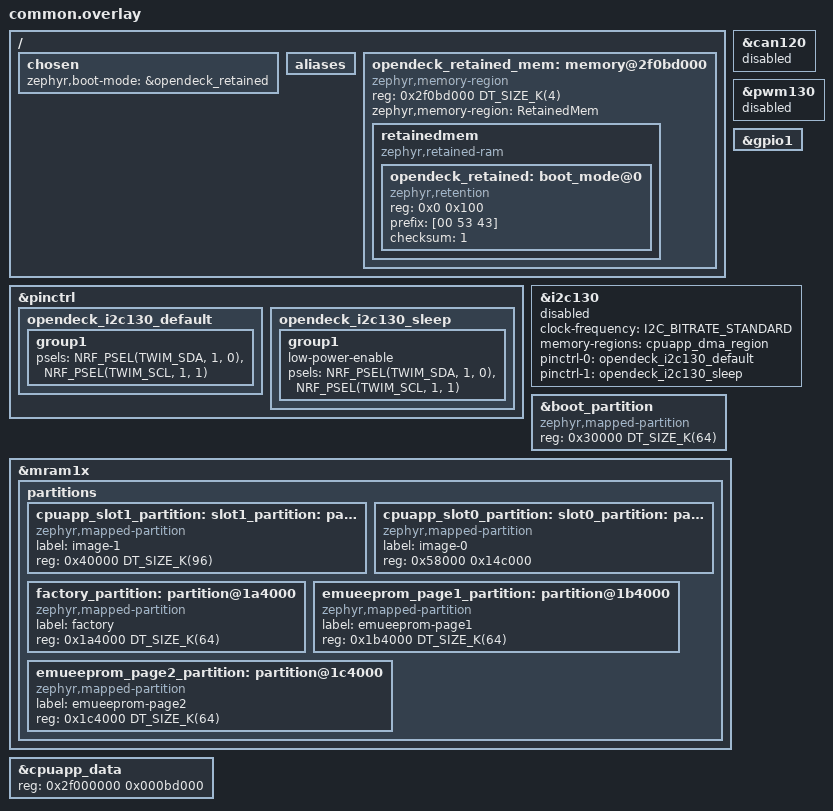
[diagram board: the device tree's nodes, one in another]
#include <zephyr/dt-bindings/i2c/i2c.h>

&can120 {
    status = "disabled";
};

/ {
    chosen {
        /delete-property/ zephyr,canbus;
    };

    aliases {
        /delete-property/ led0;
        /delete-property/ led1;
        /delete-property/ led2;
        /delete-property/ led3;
        /delete-property/ pwm-led0;
        /delete-property/ mcuboot-led0;
        /delete-property/ sw0;
        /delete-property/ sw1;
        /delete-property/ sw2;
        /delete-property/ sw3;
        /delete-property/ mcuboot-button0;
    };

    /delete-node/ buttons;
    /delete-node/ leds;
    /delete-node/ pwmleds;
};

&pinctrl {
    opendeck_i2c130_default: opendeck_i2c130_default {
        group1 {
            psels = <NRF_PSEL(TWIM_SDA, 1, 0)>,
                <NRF_PSEL(TWIM_SCL, 1, 1)>;
        };
    };

    opendeck_i2c130_sleep: opendeck_i2c130_sleep {
        group1 {
            low-power-enable;
            psels = <NRF_PSEL(TWIM_SDA, 1, 0)>,
                <NRF_PSEL(TWIM_SCL, 1, 1)>;
        };
    };
};

&pwm130 {
    status = "disabled";
};

&gpio1 {
    status = "okay";
};

&i2c130 {
    status = "disabled";
    clock-frequency = <I2C_BITRATE_STANDARD>;
    memory-regions = <&cpuapp_dma_region>;
    pinctrl-0 = <&opendeck_i2c130_default>;
    pinctrl-1 = <&opendeck_i2c130_sleep>;
    pinctrl-names = "default", "sleep";
};

&boot_partition {
    compatible = "zephyr,mapped-partition";
    reg = <0x30000 DT_SIZE_K(64)>;
};

&mram1x {
    partitions {
        ranges;
        /delete-node/ partition@40000;
        /delete-node/ partition@100000;
        /delete-node/ partition@1a4000;
        /delete-node/ partition@1ae000;
        /delete-node/ partition@1b0000;
        /delete-node/ partition@1c0000;
        /delete-node/ partition@1c2000;
        /delete-node/ partition@1c2200;

        /* image-1 is the OpenDeck bootloader; keep it before image-0 so merged images stay compact. */
        cpuapp_slot1_partition: slot1_partition: partition@40000 {
            compatible = "zephyr,mapped-partition";
            label = "image-1";
            reg = <0x40000 DT_SIZE_K(96)>;
        };

        cpuapp_slot0_partition: slot0_partition: partition@58000 {
            compatible = "zephyr,mapped-partition";
            label = "image-0";
            reg = <0x58000 0x14c000>;
        };

        factory_partition: partition@1a4000 {
            compatible = "zephyr,mapped-partition";
            label = "factory";
            reg = <0x1a4000 DT_SIZE_K(64)>;
        };

        emueeprom_page1_partition: partition@1b4000 {
            compatible = "zephyr,mapped-partition";
            label = "emueeprom-page1";
            reg = <0x1b4000 DT_SIZE_K(64)>;
        };

        emueeprom_page2_partition: partition@1c4000 {
            compatible = "zephyr,mapped-partition";
            label = "emueeprom-page2";
            reg = <0x1c4000 DT_SIZE_K(64)>;
        };
    };
};

&cpuapp_data {
    reg = <0x2f000000 0x000bd000>;
};

/ {
    chosen {
        zephyr,boot-mode = &opendeck_retained;
    };

    opendeck_retained_mem: memory@2f0bd000 {
        compatible = "zephyr,memory-region", "mmio-sram";
        reg = <0x2f0bd000 DT_SIZE_K(4)>;
        zephyr,memory-region = "RetainedMem";
        status = "okay";

        retainedmem {
            compatible = "zephyr,retained-ram";
            status = "okay";
            #address-cells = <1>;
            #size-cells = <1>;

            opendeck_retained: boot_mode@0 {
                compatible = "zephyr,retention";
                status = "okay";
                reg = <0x0 0x100>;
                prefix = [00 53 43];
                checksum = <1>;
            };
        };
    };
};
